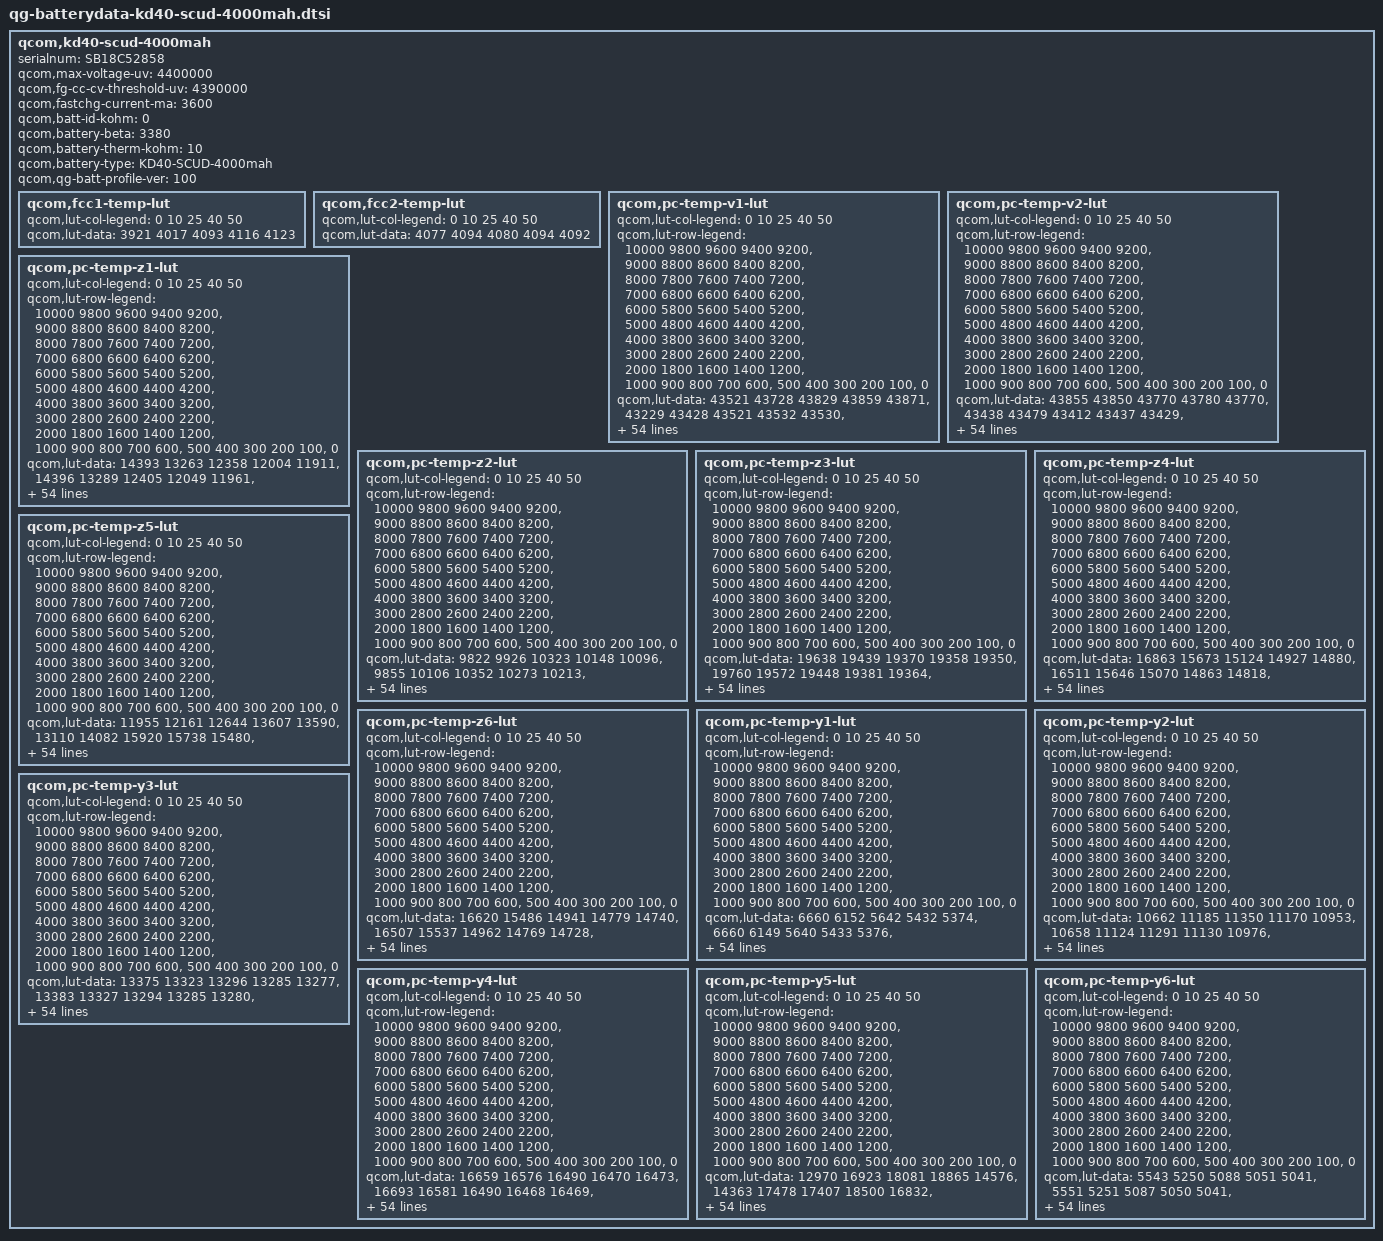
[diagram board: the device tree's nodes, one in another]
// SPDX-License-Identifier: GPL-2.0
/*
 * Copyright (c) 2018-2019, The Linux Foundation. All rights reserved.
 */

qcom,kd40-scud-4000mah {
	serialnum = "SB18C52858";
	qcom,max-voltage-uv = <4400000>;
	qcom,fg-cc-cv-threshold-uv = <4390000>;
	qcom,fastchg-current-ma = <3600>;
	qcom,batt-id-kohm = <0>;
	qcom,battery-beta = <3380>;
	qcom,battery-therm-kohm = <10>;
	qcom,battery-type = "KD40-SCUD-4000mah";
	qcom,qg-batt-profile-ver = <100>;

	qcom,fcc1-temp-lut {
		qcom,lut-col-legend = <0 10 25 40 50>;
		qcom,lut-data = <3921 4017 4093 4116 4123>;
	};

	qcom,fcc2-temp-lut {
		qcom,lut-col-legend = <0 10 25 40 50>;
		qcom,lut-data = <4077 4094 4080 4094 4092>;
	};

	qcom,pc-temp-v1-lut {
		qcom,lut-col-legend = <0 10 25 40 50>;
		qcom,lut-row-legend = <10000 9800 9600 9400 9200>,
			<9000 8800 8600 8400 8200>,
			<8000 7800 7600 7400 7200>,
			<7000 6800 6600 6400 6200>,
			<6000 5800 5600 5400 5200>,
			<5000 4800 4600 4400 4200>,
			<4000 3800 3600 3400 3200>,
			<3000 2800 2600 2400 2200>,
			<2000 1800 1600 1400 1200>,
			<1000 900 800 700 600>,
			<500 400 300 200 100>,
			<0>;
		qcom,lut-data = <43521 43728 43829 43859 43871>,
			<43229 43428 43521 43532 43530>,
			<42946 43147 43249 43263 43260>,
			<42661 42891 42990 43012 43011>,
			<42416 42644 42739 42766 42770>,
			<42184 42400 42495 42521 42530>,
			<41964 42165 42253 42284 42294>,
			<41751 41939 42015 42048 42059>,
			<41540 41718 41782 41814 41825>,
			<41338 41496 41555 41583 41594>,
			<41167 41285 41330 41357 41366>,
			<41014 41111 41122 41137 41144>,
			<40810 40956 40947 40927 40930>,
			<40491 40739 40774 40725 40725>,
			<40189 40405 40528 40519 40524>,
			<39990 40126 40231 40312 40328>,
			<39832 39964 40031 40122 40142>,
			<39707 39836 39905 39955 39966>,
			<39606 39716 39780 39797 39798>,
			<39503 39606 39639 39648 39646>,
			<39391 39484 39492 39500 39499>,
			<39278 39345 39344 39329 39326>,
			<39167 39203 39191 39139 39132>,
			<39058 39062 38981 38948 38942>,
			<38955 38916 38693 38746 38753>,
			<38857 38737 38527 38587 38596>,
			<38764 38537 38467 38486 38485>,
			<38674 38416 38419 38403 38392>,
			<38589 38346 38358 38321 38305>,
			<38510 38296 38295 38244 38227>,
			<38435 38259 38237 38177 38160>,
			<38367 38230 38182 38117 38100>,
			<38311 38200 38134 38065 38046>,
			<38262 38172 38091 38019 37995>,
			<38222 38146 38053 37976 37946>,
			<38187 38121 38016 37933 37896>,
			<38152 38094 37980 37890 37844>,
			<38117 38061 37940 37845 37792>,
			<38076 38019 37897 37798 37738>,
			<38018 37954 37834 37733 37667>,
			<37942 37852 37738 37633 37568>,
			<37838 37739 37625 37519 37454>,
			<37696 37608 37493 37391 37321>,
			<37549 37454 37345 37248 37175>,
			<37405 37290 37186 37091 37023>,
			<37280 37180 37086 36995 36935>,
			<37233 37149 37054 36964 36908>,
			<37198 37121 37036 36946 36886>,
			<37168 37103 37018 36929 36869>,
			<37132 37078 36989 36897 36832>,
			<37011 36942 36844 36728 36639>,
			<36640 36560 36446 36308 36208>,
			<36085 36002 35886 35744 35645>,
			<35328 35244 35123 34980 34877>,
			<34165 34085 33957 33808 33696>,
			<30000 30000 30000 30000 30000>;
	};

	qcom,pc-temp-v2-lut {
		qcom,lut-col-legend = <0 10 25 40 50>;
		qcom,lut-row-legend = <10000 9800 9600 9400 9200>,
			<9000 8800 8600 8400 8200>,
			<8000 7800 7600 7400 7200>,
			<7000 6800 6600 6400 6200>,
			<6000 5800 5600 5400 5200>,
			<5000 4800 4600 4400 4200>,
			<4000 3800 3600 3400 3200>,
			<3000 2800 2600 2400 2200>,
			<2000 1800 1600 1400 1200>,
			<1000 900 800 700 600>,
			<500 400 300 200 100>,
			<0>;
		qcom,lut-data = <43855 43850 43770 43780 43770>,
			<43438 43479 43412 43437 43429>,
			<43076 43148 43091 43127 43120>,
			<42780 42864 42815 42854 42849>,
			<42531 42615 42572 42610 42606>,
			<42282 42368 42331 42368 42364>,
			<42031 42126 42093 42129 42123>,
			<41796 41890 41859 41893 41887>,
			<41581 41661 41630 41662 41658>,
			<41377 41438 41406 41434 41432>,
			<41187 41223 41184 41209 41209>,
			<41005 41015 40967 40990 40989>,
			<40799 40822 40768 40779 40775>,
			<40570 40645 40588 40578 40569>,
			<40304 40435 40391 40378 40369>,
			<39931 40139 40141 40176 40176>,
			<39603 39868 39911 39985 39992>,
			<39453 39708 39760 39815 39818>,
			<39347 39574 39635 39655 39651>,
			<39200 39391 39495 39503 39497>,
			<39015 39169 39343 39358 39352>,
			<38842 38973 39161 39179 39176>,
			<38688 38805 38912 38939 38940>,
			<38545 38653 38686 38722 38724>,
			<38413 38518 38534 38562 38563>,
			<38291 38397 38412 38429 38428>,
			<38177 38291 38305 38319 38317>,
			<38072 38196 38211 38224 38222>,
			<37998 38107 38129 38139 38135>,
			<37947 38021 38056 38061 38055>,
			<37905 37948 37989 37993 37985>,
			<37870 37885 37925 37933 37922>,
			<37838 37835 37867 37877 37866>,
			<37806 37800 37816 37820 37813>,
			<37774 37772 37770 37764 37761>,
			<37733 37741 37725 37699 37688>,
			<37677 37709 37683 37627 37591>,
			<37617 37672 37635 37554 37497>,
			<37559 37623 37576 37480 37413>,
			<37495 37561 37509 37405 37334>,
			<37421 37483 37430 37329 37260>,
			<37331 37390 37343 37246 37179>,
			<37227 37271 37224 37135 37069>,
			<37103 37131 37096 37008 36944>,
			<36987 36986 36943 36861 36801>,
			<36905 36911 36886 36818 36760>,
			<36870 36885 36876 36808 36753>,
			<36833 36860 36859 36796 36739>,
			<36783 36817 36839 36775 36719>,
			<36704 36746 36792 36725 36662>,
			<36515 36539 36598 36494 36402>,
			<36117 36092 36153 36024 35926>,
			<35514 35465 35551 35408 35299>,
			<34652 34592 34743 34568 34452>,
			<33278 33349 33551 33346 33184>,
			<28800 28700 28452 28672 28678>;
	};

	qcom,pc-temp-z1-lut {
		qcom,lut-col-legend = <0 10 25 40 50>;
		qcom,lut-row-legend = <10000 9800 9600 9400 9200>,
			<9000 8800 8600 8400 8200>,
			<8000 7800 7600 7400 7200>,
			<7000 6800 6600 6400 6200>,
			<6000 5800 5600 5400 5200>,
			<5000 4800 4600 4400 4200>,
			<4000 3800 3600 3400 3200>,
			<3000 2800 2600 2400 2200>,
			<2000 1800 1600 1400 1200>,
			<1000 900 800 700 600>,
			<500 400 300 200 100>,
			<0>;
		qcom,lut-data = <14393 13263 12358 12004 11911>,
			<14396 13289 12405 12049 11961>,
			<14468 13271 12404 12051 11964>,
			<14441 13287 12397 12049 11964>,
			<14422 13266 12379 12045 11965>,
			<14420 13254 12371 12040 11963>,
			<14421 13248 12369 12041 11966>,
			<14417 13242 12366 12041 11968>,
			<14388 13236 12363 12043 11970>,
			<14349 13221 12363 12045 11971>,
			<14337 13209 12371 12046 11972>,
			<14327 13205 12377 12047 11972>,
			<14305 13189 12374 12047 11973>,
			<14218 13171 12368 12047 11974>,
			<14139 13139 12358 12047 11975>,
			<14102 13124 12345 12046 11976>,
			<14077 13131 12343 12046 11976>,
			<14074 13143 12352 12048 11978>,
			<14081 13156 12362 12050 11980>,
			<14084 13172 12370 12053 11983>,
			<14077 13188 12376 12055 11986>,
			<14069 13207 12382 12057 11987>,
			<14087 13221 12386 12059 11987>,
			<14131 13226 12391 12062 11988>,
			<14150 13231 12396 12066 11992>,
			<14165 13237 12401 12070 11997>,
			<14177 13244 12406 12074 12001>,
			<14175 13251 12412 12079 12005>,
			<14171 13256 12417 12082 12008>,
			<14179 13259 12422 12085 12011>,
			<14215 13260 12427 12088 12014>,
			<14240 13261 12432 12091 12017>,
			<14253 13272 12437 12095 12020>,
			<14265 13297 12442 12099 12023>,
			<14271 13310 12448 12103 12025>,
			<14276 13314 12455 12107 12028>,
			<14285 13320 12464 12112 12031>,
			<14302 13343 12472 12116 12033>,
			<14321 13370 12480 12119 12036>,
			<14339 13381 12488 12124 12039>,
			<14356 13389 12495 12129 12043>,
			<14361 13400 12503 12135 12047>,
			<14356 13420 12512 12138 12051>,
			<14378 13437 12521 12142 12054>,
			<14400 13446 12528 12146 12057>,
			<14390 13432 12534 12151 12061>,
			<14400 13436 12538 12150 12061>,
			<14391 13434 12540 12151 12062>,
			<14384 13436 12541 12154 12064>,
			<14413 13462 12544 12159 12068>,
			<14383 13465 12552 12165 12075>,
			<14404 13477 12571 12175 12083>,
			<14445 13528 12594 12190 12097>,
			<14456 13585 12626 12214 12116>,
			<14456 13585 12626 12214 12116>,
			<14456 13585 12626 12214 12116>;
	};

	qcom,pc-temp-z2-lut {
		qcom,lut-col-legend = <0 10 25 40 50>;
		qcom,lut-row-legend = <10000 9800 9600 9400 9200>,
			<9000 8800 8600 8400 8200>,
			<8000 7800 7600 7400 7200>,
			<7000 6800 6600 6400 6200>,
			<6000 5800 5600 5400 5200>,
			<5000 4800 4600 4400 4200>,
			<4000 3800 3600 3400 3200>,
			<3000 2800 2600 2400 2200>,
			<2000 1800 1600 1400 1200>,
			<1000 900 800 700 600>,
			<500 400 300 200 100>,
			<0>;
		qcom,lut-data = <9822 9926 10323 10148 10096>,
			<9855 10106 10352 10273 10213>,
			<9988 10186 10378 10300 10231>,
			<9962 10177 10365 10301 10190>,
			<9983 10173 10344 10314 10210>,
			<9993 10168 10267 10329 10280>,
			<9995 10162 10247 10284 10253>,
			<9999 10157 10238 10267 10243>,
			<10006 10153 10235 10269 10248>,
			<10014 10140 10239 10272 10256>,
			<10026 10122 10248 10274 10273>,
			<10043 10111 10260 10274 10291>,
			<10049 10103 10283 10274 10286>,
			<10046 10095 10307 10276 10264>,
			<10041 10080 10307 10281 10235>,
			<10027 10071 10299 10290 10193>,
			<10009 10078 10297 10287 10176>,
			<10007 10093 10304 10253 10190>,
			<10016 10118 10316 10228 10212>,
			<10023 10158 10362 10240 10231>,
			<10023 10197 10417 10272 10256>,
			<10023 10234 10448 10359 10347>,
			<10023 10272 10469 10533 10561>,
			<10021 10322 10468 10561 10616>,
			<10021 10360 10450 10397 10474>,
			<10025 10351 10429 10300 10382>,
			<10031 10320 10400 10452 10468>,
			<10045 10314 10381 10625 10566>,
			<10065 10333 10407 10594 10508>,
			<10083 10352 10449 10490 10349>,
			<10099 10367 10454 10412 10238>,
			<10115 10382 10450 10340 10150>,
			<10129 10391 10448 10318 10121>,
			<10142 10399 10447 10327 10139>,
			<10156 10407 10447 10342 10170>,
			<10170 10418 10461 10373 10216>,
			<10185 10431 10486 10412 10275>,
			<10200 10445 10515 10439 10329>,
			<10219 10462 10549 10462 10381>,
			<10252 10485 10569 10488 10405>,
			<10293 10513 10582 10523 10415>,
			<10324 10531 10589 10544 10424>,
			<10350 10541 10592 10555 10436>,
			<10339 10554 10598 10547 10438>,
			<10145 10588 10610 10486 10421>,
			<9688 10818 10666 10472 10415>,
			<9746 10846 10647 10462 10445>,
			<9796 10870 10654 10494 10420>,
			<9826 11286 10660 10492 10464>,
			<9883 11781 10712 10599 10550>,
			<9865 11162 10749 10580 10466>,
			<9756 10869 10705 10364 10242>,
			<9674 10797 10614 10276 10157>,
			<9595 10723 10544 10200 10085>,
			<9595 10723 10544 10200 10085>,
			<9595 10723 10544 10200 10085>;
	};

	qcom,pc-temp-z3-lut {
		qcom,lut-col-legend = <0 10 25 40 50>;
		qcom,lut-row-legend = <10000 9800 9600 9400 9200>,
			<9000 8800 8600 8400 8200>,
			<8000 7800 7600 7400 7200>,
			<7000 6800 6600 6400 6200>,
			<6000 5800 5600 5400 5200>,
			<5000 4800 4600 4400 4200>,
			<4000 3800 3600 3400 3200>,
			<3000 2800 2600 2400 2200>,
			<2000 1800 1600 1400 1200>,
			<1000 900 800 700 600>,
			<500 400 300 200 100>,
			<0>;
		qcom,lut-data = <19638 19439 19370 19358 19350>,
			<19760 19572 19448 19381 19364>,
			<19757 19607 19456 19392 19374>,
			<19681 19653 19449 19390 19379>,
			<19671 19708 19492 19398 19382>,
			<19673 19706 19509 19442 19419>,
			<19676 19703 19504 19440 19419>,
			<19679 19695 19500 19436 19419>,
			<19684 19686 19495 19430 19416>,
			<19689 19679 19489 19424 19413>,
			<19690 19672 19479 19417 19410>,
			<19690 19651 19466 19410 19407>,
			<19696 19615 19451 19404 19401>,
			<19728 19608 19438 19399 19392>,
			<19753 19623 19444 19398 19386>,
			<19741 19632 19465 19398 19383>,
			<19715 19612 19469 19397 19380>,
			<19693 19581 19448 19388 19377>,
			<19674 19558 19430 19377 19373>,
			<19663 19540 19421 19371 19366>,
			<19657 19534 19416 19366 19357>,
			<19654 19535 19419 19371 19360>,
			<19657 19537 19427 19387 19372>,
			<19666 19541 19431 19389 19375>,
			<19677 19546 19435 19369 19356>,
			<19691 19548 19436 19357 19344>,
			<19704 19551 19425 19371 19381>,
			<19714 19551 19416 19393 19425>,
			<19721 19550 19419 19408 19425>,
			<19722 19549 19425 19421 19417>,
			<19720 19547 19432 19422 19408>,
			<19718 19544 19442 19415 19396>,
			<19712 19541 19444 19407 19385>,
			<19703 19538 19443 19400 19378>,
			<19693 19534 19441 19393 19372>,
			<19680 19529 19437 19386 19364>,
			<19666 19523 19432 19379 19357>,
			<19649 19518 19428 19374 19353>,
			<19631 19512 19425 19369 19351>,
			<19611 19509 19421 19368 19350>,
			<19594 19506 19415 19368 19351>,
			<19587 19502 19412 19368 19352>,
			<19584 19496 19412 19367 19356>,
			<19541 19491 19411 19367 19358>,
			<19422 19485 19407 19366 19359>,
			<19277 19441 19390 19355 19348>,
			<19273 19428 19390 19354 19340>,
			<19269 19424 19376 19344 19336>,
			<19267 19353 19372 19341 19328>,
			<19266 19285 19369 19330 19319>,
			<19266 19386 19364 19336 19337>,
			<19268 19425 19363 19360 19357>,
			<19270 19425 19363 19363 19357>,
			<19272 19413 19362 19365 19361>,
			<19272 19413 19362 19365 19361>,
			<19272 19413 19362 19365 19361>;
	};

	qcom,pc-temp-z4-lut {
		qcom,lut-col-legend = <0 10 25 40 50>;
		qcom,lut-row-legend = <10000 9800 9600 9400 9200>,
			<9000 8800 8600 8400 8200>,
			<8000 7800 7600 7400 7200>,
			<7000 6800 6600 6400 6200>,
			<6000 5800 5600 5400 5200>,
			<5000 4800 4600 4400 4200>,
			<4000 3800 3600 3400 3200>,
			<3000 2800 2600 2400 2200>,
			<2000 1800 1600 1400 1200>,
			<1000 900 800 700 600>,
			<500 400 300 200 100>,
			<0>;
		qcom,lut-data = <16863 15673 15124 14927 14880>,
			<16511 15646 15070 14863 14818>,
			<17225 15311 14929 14810 14776>,
			<17482 15384 14846 14771 14746>,
			<16916 15569 14933 14768 14740>,
			<16522 15355 14951 14835 14812>,
			<16238 15205 14885 14801 14784>,
			<16017 15106 14839 14774 14761>,
			<15852 15031 14803 14756 14746>,
			<15714 14975 14785 14744 14735>,
			<15573 14931 14779 14738 14727>,
			<15439 14883 14773 14734 14722>,
			<15354 14838 14756 14727 14718>,
			<15310 14825 14738 14718 14715>,
			<15269 14828 14740 14712 14711>,
			<15212 14829 14746 14709 14706>,
			<15150 14809 14743 14705 14701>,
			<15095 14779 14717 14701 14695>,
			<15045 14760 14703 14697 14690>,
			<15009 14746 14704 14693 14685>,
			<14988 14739 14706 14689 14681>,
			<14971 14736 14708 14694 14687>,
			<14951 14735 14712 14717 14715>,
			<14929 14740 14745 14753 14753>,
			<14906 14751 14870 14834 14821>,
			<14880 14794 14923 14876 14858>,
			<14856 14885 14900 14846 14804>,
			<14838 14911 14867 14798 14734>,
			<14823 14902 14840 14763 14720>,
			<14816 14888 14812 14733 14714>,
			<14812 14866 14786 14720 14710>,
			<14809 14838 14762 14714 14707>,
			<14805 14816 14745 14709 14704>,
			<14800 14796 14733 14704 14698>,
			<14792 14778 14725 14701 14694>,
			<14782 14761 14721 14703 14697>,
			<14772 14746 14717 14705 14700>,
			<14763 14733 14715 14704 14701>,
			<14754 14723 14712 14703 14701>,
			<14747 14723 14713 14703 14703>,
			<14741 14723 14718 14711 14709>,
			<14736 14722 14720 14715 14712>,
			<14732 14715 14711 14708 14707>,
			<14771 14708 14705 14705 14704>,
			<14850 14700 14703 14708 14708>,
			<14939 14676 14669 14676 14677>,
			<14933 14680 14661 14669 14672>,
			<14926 14673 14658 14661 14660>,
			<14919 14742 14647 14643 14644>,
			<14911 14809 14642 14639 14636>,
			<14911 14705 14660 14656 14645>,
			<14938 14684 14684 14659 14658>,
			<14965 14699 14691 14661 14663>,
			<14990 14728 14698 14663 14662>,
			<14990 14728 14698 14663 14662>,
			<14990 14728 14698 14663 14662>;
	};

	qcom,pc-temp-z5-lut {
		qcom,lut-col-legend = <0 10 25 40 50>;
		qcom,lut-row-legend = <10000 9800 9600 9400 9200>,
			<9000 8800 8600 8400 8200>,
			<8000 7800 7600 7400 7200>,
			<7000 6800 6600 6400 6200>,
			<6000 5800 5600 5400 5200>,
			<5000 4800 4600 4400 4200>,
			<4000 3800 3600 3400 3200>,
			<3000 2800 2600 2400 2200>,
			<2000 1800 1600 1400 1200>,
			<1000 900 800 700 600>,
			<500 400 300 200 100>,
			<0>;
		qcom,lut-data = <11955 12161 12644 13607 13590>,
			<13110 14082 15920 15738 15480>,
			<13222 16305 17833 17849 17703>,
			<13260 16001 19078 18722 19600>,
			<13985 14468 18179 19651 20699>,
			<14533 15029 17106 19117 19705>,
			<14961 15591 17662 19504 20304>,
			<15292 16161 18361 19944 21031>,
			<15523 16794 19378 20568 21918>,
			<15712 17669 19724 21036 22760>,
			<15867 18322 19522 20995 23575>,
			<16004 18276 19223 20722 24149>,
			<16284 18108 18874 20647 23738>,
			<17002 18590 18568 20772 22653>,
			<17471 21540 19871 21392 22482>,
			<17401 23222 23479 22788 23040>,
			<17267 22281 24349 23284 23688>,
			<17203 21284 23285 22600 24615>,
			<17153 21347 22698 22122 25301>,
			<17101 21876 23124 22039 24775>,
			<17051 22897 23987 21949 23788>,
			<17067 25775 26569 24670 25333>,
			<17352 29537 30494 32369 31196>,
			<18042 35232 31652 33417 32192>,
			<19008 40412 31794 23767 22636>,
			<20656 42405 31056 17640 16292>,
			<22822 43942 25450 17666 19259>,
			<25709 43862 20879 18286 23411>,
			<29023 41217 20785 20354 25015>,
			<31979 38390 20844 23884 25980>,
			<35159 36369 21698 25856 25880>,
			<36898 34914 24711 27058 24742>,
			<37514 34438 27493 28145 24316>,
			<37852 34156 29967 29368 25456>,
			<37355 34009 32011 30103 26403>,
			<35881 33918 33840 30228 26264>,
			<34325 33890 35049 30237 25942>,
			<32058 33998 35005 29757 25607>,
			<29831 34237 34578 28314 25169>,
			<27965 34973 33538 27058 24499>,
			<26545 36445 30643 25797 23263>,
			<27007 36513 29208 24897 22669>,
			<29147 33560 29462 24448 23642>,
			<25662 33223 29323 24007 24145>,
			<17977 34550 28050 23483 24026>,
			<11704 31001 28545 23762 23188>,
			<11683 24158 28957 23175 20267>,
			<11621 23506 23639 21341 20127>,
			<11582 16781 23353 23010 21004>,
			<11583 12079 23771 21191 20431>,
			<11606 22306 20897 19327 22265>,
			<11704 21837 17577 21134 22879>,
			<11581 19332 16501 20390 20230>,
			<11465 16541 15594 18936 19056>,
			<11465 16541 15594 18936 19056>,
			<11465 16541 15594 18936 19056>;
	};

	qcom,pc-temp-z6-lut {
		qcom,lut-col-legend = <0 10 25 40 50>;
		qcom,lut-row-legend = <10000 9800 9600 9400 9200>,
			<9000 8800 8600 8400 8200>,
			<8000 7800 7600 7400 7200>,
			<7000 6800 6600 6400 6200>,
			<6000 5800 5600 5400 5200>,
			<5000 4800 4600 4400 4200>,
			<4000 3800 3600 3400 3200>,
			<3000 2800 2600 2400 2200>,
			<2000 1800 1600 1400 1200>,
			<1000 900 800 700 600>,
			<500 400 300 200 100>,
			<0>;
		qcom,lut-data = <16620 15486 14941 14779 14740>,
			<16507 15537 14962 14769 14728>,
			<16785 15400 14903 14752 14715>,
			<16839 15444 14862 14734 14705>,
			<16562 15546 14920 14737 14704>,
			<16374 15443 14936 14790 14756>,
			<16240 15367 14903 14774 14745>,
			<16135 15313 14881 14761 14735>,
			<16058 15271 14863 14750 14727>,
			<15992 15241 14851 14742 14721>,
			<15921 15214 14843 14736 14716>,
			<15850 15175 14836 14730 14712>,
			<15799 15133 14819 14723 14707>,
			<15768 15121 14803 14717 14700>,
			<15736 15121 14805 14713 14695>,
			<15689 15121 14816 14712 14691>,
			<15636 15103 14816 14709 14687>,
			<15596 15077 14795 14703 14684>,
			<15561 15062 14782 14696 14679>,
			<15544 15050 14779 14690 14673>,
			<15539 15047 14778 14687 14667>,
			<15537 15049 14780 14691 14671>,
			<15537 15052 14786 14708 14690>,
			<15540 15058 14806 14728 14708>,
			<15542 15067 14862 14753 14729>,
			<15545 15090 14886 14765 14738>,
			<15548 15131 14871 14760 14736>,
			<15552 15142 14854 14753 14731>,
			<15556 15140 14844 14747 14726>,
			<15557 15135 14837 14742 14720>,
			<15559 15126 14831 14736 14714>,
			<15559 15114 14826 14731 14706>,
			<15559 15106 14821 14725 14700>,
			<15559 15099 14817 14719 14693>,
			<15556 15092 14812 14714 14689>,
			<15551 15085 14809 14711 14685>,
			<15546 15080 14806 14709 14683>,
			<15541 15076 14804 14706 14681>,
			<15537 15073 14803 14703 14679>,
			<15532 15074 14802 14703 14679>,
			<15528 15079 14804 14707 14683>,
			<15529 15081 14804 14709 14685>,
			<15534 15079 14802 14706 14685>,
			<15532 15079 14800 14705 14686>,
			<15519 15079 14799 14706 14689>,
			<15492 15054 14778 14688 14670>,
			<15488 15049 14774 14684 14664>,
			<15482 15045 14766 14675 14657>,
			<15481 15040 14760 14666 14645>,
			<15480 15038 14758 14661 14638>,
			<15485 15049 14765 14671 14652>,
			<15512 15071 14779 14687 14671>,
			<15536 15087 14788 14694 14677>,
			<15573 15114 14798 14701 14683>,
			<15573 15114 14798 14701 14683>,
			<15573 15114 14798 14701 14683>;
	};

	qcom,pc-temp-y1-lut {
		qcom,lut-col-legend = <0 10 25 40 50>;
		qcom,lut-row-legend = <10000 9800 9600 9400 9200>,
			<9000 8800 8600 8400 8200>,
			<8000 7800 7600 7400 7200>,
			<7000 6800 6600 6400 6200>,
			<6000 5800 5600 5400 5200>,
			<5000 4800 4600 4400 4200>,
			<4000 3800 3600 3400 3200>,
			<3000 2800 2600 2400 2200>,
			<2000 1800 1600 1400 1200>,
			<1000 900 800 700 600>,
			<500 400 300 200 100>,
			<0>;
		qcom,lut-data = <6660 6152 5642 5432 5374>,
			<6660 6149 5640 5433 5376>,
			<6660 6145 5639 5433 5378>,
			<6660 6141 5637 5433 5378>,
			<6660 6137 5635 5432 5379>,
			<6659 6134 5634 5432 5379>,
			<6658 6131 5631 5432 5378>,
			<6657 6129 5629 5432 5377>,
			<6656 6133 5627 5431 5379>,
			<6656 6137 5625 5430 5380>,
			<6660 6135 5625 5430 5380>,
			<6670 6131 5624 5429 5380>,
			<6673 6128 5623 5429 5380>,
			<6676 6119 5621 5430 5380>,
			<6677 6115 5620 5430 5381>,
			<6684 6122 5630 5431 5382>,
			<6692 6129 5640 5432 5384>,
			<6691 6136 5638 5433 5384>,
			<6685 6142 5634 5435 5385>,
			<6685 6141 5634 5435 5385>,
			<6691 6135 5636 5436 5387>,
			<6696 6134 5638 5436 5388>,
			<6697 6138 5643 5438 5389>,
			<6698 6141 5647 5440 5390>,
			<6706 6143 5649 5442 5392>,
			<6718 6144 5652 5444 5394>,
			<6721 6149 5655 5446 5395>,
			<6721 6159 5659 5448 5397>,
			<6722 6163 5664 5451 5399>,
			<6727 6163 5668 5453 5400>,
			<6730 6161 5673 5456 5402>,
			<6724 6155 5678 5459 5405>,
			<6714 6150 5683 5462 5407>,
			<6707 6155 5687 5465 5410>,
			<6700 6166 5693 5469 5412>,
			<6699 6170 5697 5472 5415>,
			<6713 6170 5701 5474 5417>,
			<6722 6171 5704 5476 5419>,
			<6718 6180 5706 5477 5421>,
			<6715 6192 5709 5479 5422>,
			<6727 6203 5712 5482 5424>,
			<6738 6198 5721 5485 5427>,
			<6759 6218 5721 5488 5428>,
			<6768 6224 5732 5491 5433>,
			<6779 6233 5736 5497 5436>,
			<6778 6248 5751 5502 5441>,
			<6778 6229 5757 5503 5441>,
			<6782 6249 5758 5504 5441>,
			<6793 6242 5767 5505 5441>,
			<6773 6245 5765 5503 5441>,
			<6778 6264 5770 5507 5445>,
			<6813 6273 5784 5516 5450>,
			<6825 6285 5807 5530 5461>,
			<6851 6297 5839 5548 5477>,
			<6851 6297 5839 5548 5477>,
			<6851 6297 5839 5548 5477>;
	};

	qcom,pc-temp-y2-lut {
		qcom,lut-col-legend = <0 10 25 40 50>;
		qcom,lut-row-legend = <10000 9800 9600 9400 9200>,
			<9000 8800 8600 8400 8200>,
			<8000 7800 7600 7400 7200>,
			<7000 6800 6600 6400 6200>,
			<6000 5800 5600 5400 5200>,
			<5000 4800 4600 4400 4200>,
			<4000 3800 3600 3400 3200>,
			<3000 2800 2600 2400 2200>,
			<2000 1800 1600 1400 1200>,
			<1000 900 800 700 600>,
			<500 400 300 200 100>,
			<0>;
		qcom,lut-data = <10662 11185 11350 11170 10953>,
			<10658 11124 11291 11130 10976>,
			<10654 11065 11233 11087 10981>,
			<10648 11011 11179 11044 10973>,
			<10643 10961 11127 11003 10957>,
			<10637 10917 11076 10964 10934>,
			<10627 10876 11022 10920 10882>,
			<10612 10842 10992 10895 10842>,
			<10569 10812 10983 10884 10824>,
			<10528 10789 10975 10878 10812>,
			<10585 10780 10954 10878 10803>,
			<10734 10775 10917 10876 10796>,
			<10824 10792 10888 10857 10794>,
			<10891 10885 10855 10789 10792>,
			<10915 10959 10844 10762 10792>,
			<10888 11002 10920 10802 10789>,
			<10861 11034 11021 10853 10790>,
			<10887 11061 11075 10888 10816>,
			<10943 11083 11121 10928 10862>,
			<10972 11094 11195 11012 10913>,
			<10987 11100 11302 11148 10972>,
			<11007 11114 11335 11188 11007>,
			<11036 11152 11276 11162 11025>,
			<11059 11186 11231 11137 11041>,
			<11066 11206 11250 11126 11064>,
			<11072 11224 11281 11119 11091>,
			<11088 11246 11295 11154 11114>,
			<11118 11268 11303 11237 11138>,
			<11128 11283 11309 11269 11166>,
			<11128 11293 11332 11280 11215>,
			<11125 11301 11349 11294 11243>,
			<11086 11308 11337 11333 11260>,
			<11022 11311 11320 11361 11282>,
			<10977 11296 11312 11342 11313>,
			<10934 11259 11306 11299 11346>,
			<10760 11225 11293 11255 11337>,
			<10100 11190 11264 11198 11254>,
			<9716 11152 11247 11179 11181>,
			<9689 11109 11246 11203 11129>,
			<9678 11058 11240 11196 11106>,
			<9674 11002 11206 11172 11064>,
			<9670 10965 11212 11172 11092>,
			<9669 10911 11205 11143 11112>,
			<9664 10807 11181 11155 11096>,
			<9659 10483 11135 11144 11031>,
			<9657 10538 11014 10976 10908>,
			<9656 10400 10982 10958 10859>,
			<9655 10116 10962 10962 10849>,
			<9654 9807 10942 10976 10900>,
			<9654 9749 10925 11011 10894>,
			<9653 9698 10901 10956 10822>,
			<9653 9674 10806 10897 10774>,
			<9653 9662 10713 10820 10667>,
			<9653 9656 10626 10724 10590>,
			<9653 9656 10626 10724 10590>,
			<9653 9656 10626 10724 10590>;
	};

	qcom,pc-temp-y3-lut {
		qcom,lut-col-legend = <0 10 25 40 50>;
		qcom,lut-row-legend = <10000 9800 9600 9400 9200>,
			<9000 8800 8600 8400 8200>,
			<8000 7800 7600 7400 7200>,
			<7000 6800 6600 6400 6200>,
			<6000 5800 5600 5400 5200>,
			<5000 4800 4600 4400 4200>,
			<4000 3800 3600 3400 3200>,
			<3000 2800 2600 2400 2200>,
			<2000 1800 1600 1400 1200>,
			<1000 900 800 700 600>,
			<500 400 300 200 100>,
			<0>;
		qcom,lut-data = <13375 13323 13296 13285 13277>,
			<13383 13327 13294 13285 13280>,
			<13391 13330 13294 13285 13282>,
			<13399 13333 13293 13285 13283>,
			<13405 13336 13294 13285 13283>,
			<13409 13339 13294 13286 13283>,
			<13411 13342 13294 13286 13282>,
			<13414 13344 13295 13287 13282>,
			<13423 13345 13296 13288 13284>,
			<13432 13347 13297 13289 13286>,
			<13440 13348 13299 13290 13287>,
			<13446 13350 13302 13291 13288>,
			<13442 13354 13307 13291 13288>,
			<13411 13359 13314 13292 13289>,
			<13388 13361 13316 13292 13289>,
			<13379 13353 13312 13291 13289>,
			<13374 13345 13308 13291 13289>,
			<13374 13343 13308 13292 13290>,
			<13376 13342 13307 13295 13291>,
			<13374 13338 13308 13296 13292>,
			<13367 13331 13310 13297 13294>,
			<13360 13326 13310 13297 13294>,
			<13356 13324 13304 13291 13288>,
			<13353 13322 13297 13286 13282>,
			<13349 13319 13295 13284 13281>,
			<13344 13317 13293 13283 13280>,
			<13337 13317 13292 13283 13280>,
			<13328 13317 13291 13282 13280>,
			<13325 13316 13291 13282 13280>,
			<13325 13314 13293 13281 13279>,
			<13325 13312 13294 13281 13278>,
			<13329 13311 13294 13281 13278>,
			<13336 13311 13294 13282 13278>,
			<13341 13312 13294 13282 13279>,
			<13345 13315 13294 13282 13280>,
			<13351 13318 13294 13282 13280>,
			<13358 13320 13294 13282 13279>,
			<13363 13323 13295 13282 13278>,
			<13365 13326 13296 13283 13279>,
			<13373 13328 13297 13283 13279>,
			<13407 13330 13297 13284 13280>,
			<13433 13330 13296 13284 13281>,
			<13431 13328 13293 13283 13281>,
			<13504 13328 13294 13283 13281>,
			<13620 13329 13293 13281 13277>,
			<13810 13342 13298 13285 13282>,
			<13926 13348 13303 13289 13287>,
			<14058 13351 13305 13293 13290>,
			<14185 13365 13312 13296 13292>,
			<14307 13408 13318 13299 13293>,
			<14414 13444 13316 13293 13288>,
			<14527 13485 13317 13292 13288>,
			<14703 13613 13328 13299 13292>,
			<14940 13896 13342 13306 13302>,
			<14940 13896 13342 13306 13302>,
			<14940 13896 13342 13306 13302>;
	};

	qcom,pc-temp-y4-lut {
		qcom,lut-col-legend = <0 10 25 40 50>;
		qcom,lut-row-legend = <10000 9800 9600 9400 9200>,
			<9000 8800 8600 8400 8200>,
			<8000 7800 7600 7400 7200>,
			<7000 6800 6600 6400 6200>,
			<6000 5800 5600 5400 5200>,
			<5000 4800 4600 4400 4200>,
			<4000 3800 3600 3400 3200>,
			<3000 2800 2600 2400 2200>,
			<2000 1800 1600 1400 1200>,
			<1000 900 800 700 600>,
			<500 400 300 200 100>,
			<0>;
		qcom,lut-data = <16659 16576 16490 16470 16473>,
			<16693 16581 16490 16468 16469>,
			<16730 16588 16491 16467 16466>,
			<16765 16595 16492 16466 16464>,
			<16793 16600 16494 16466 16463>,
			<16809 16603 16496 16466 16463>,
			<16818 16603 16499 16467 16465>,
			<16825 16605 16502 16468 16466>,
			<16832 16617 16506 16470 16466>,
			<16842 16632 16510 16472 16465>,
			<16884 16641 16513 16474 16466>,
			<16969 16649 16516 16477 16469>,
			<17043 16681 16522 16482 16471>,
			<17123 16778 16539 16490 16475>,
			<17147 16817 16556 16499 16480>,
			<16924 16778 16567 16507 16485>,
			<16707 16745 16581 16515 16492>,
			<16730 16746 16610 16526 16500>,
			<16782 16748 16649 16540 16511>,
			<16782 16730 16676 16567 16531>,
			<16739 16662 16698 16611 16564>,
			<16701 16612 16697 16618 16571>,
			<16674 16581 16600 16562 16537>,
			<16650 16560 16512 16508 16501>,
			<16626 16547 16492 16483 16480>,
			<16603 16539 16481 16468 16466>,
			<16584 16535 16481 16468 16466>,
			<16566 16532 16483 16469 16466>,
			<16561 16528 16487 16472 16468>,
			<16565 16522 16491 16479 16475>,
			<16571 16516 16495 16488 16484>,
			<16577 16511 16497 16500 16495>,
			<16584 16508 16499 16510 16506>,
			<16595 16512 16501 16513 16519>,
			<16612 16521 16503 16514 16530>,
			<16638 16533 16504 16510 16525>,
			<16686 16549 16504 16494 16497>,
			<16726 16565 16504 16482 16479>,
			<16751 16579 16499 16474 16471>,
			<16760 16589 16495 16473 16471>,
			<16760 16595 16494 16478 16479>,
			<16744 16583 16495 16481 16484>,
			<16710 16559 16482 16468 16468>,
			<16699 16566 16488 16472 16471>,
			<16701 16587 16477 16450 16446>,
			<16719 16596 16490 16462 16460>,
			<16739 16622 16504 16474 16478>,
			<16773 16689 16524 16501 16516>,
			<16822 16745 16554 16542 16563>,
			<16877 16790 16602 16581 16593>,
			<16897 16823 16588 16523 16510>,
			<16879 16814 16570 16491 16484>,
			<16858 16839 16601 16504 16489>,
			<16864 16900 16668 16546 16523>,
			<16864 16900 16668 16546 16523>,
			<16864 16900 16668 16546 16523>;
	};

	qcom,pc-temp-y5-lut {
		qcom,lut-col-legend = <0 10 25 40 50>;
		qcom,lut-row-legend = <10000 9800 9600 9400 9200>,
			<9000 8800 8600 8400 8200>,
			<8000 7800 7600 7400 7200>,
			<7000 6800 6600 6400 6200>,
			<6000 5800 5600 5400 5200>,
			<5000 4800 4600 4400 4200>,
			<4000 3800 3600 3400 3200>,
			<3000 2800 2600 2400 2200>,
			<2000 1800 1600 1400 1200>,
			<1000 900 800 700 600>,
			<500 400 300 200 100>,
			<0>;
		qcom,lut-data = <12970 16923 18081 18865 14576>,
			<14363 17478 17407 18500 16832>,
			<15484 17890 16754 18144 18114>,
			<16290 18147 16159 17806 18687>,
			<16737 18242 15657 17495 18811>,
			<16747 18162 15282 17218 18506>,
			<16245 17913 14996 16961 16720>,
			<15957 17542 14757 16734 15709>,
			<17334 16678 14480 16507 16543>,
			<18910 15765 14289 16272 17460>,
			<17718 15335 14377 16052 17342>,
			<14861 15020 14625 15813 16907>,
			<14761 14933 14801 15437 16489>,
			<17584 14932 14951 14839 16050>,
			<18955 15167 14984 14309 15603>,
			<18128 17137 14478 13818 15102>,
			<17348 19096 13990 13550 14692>,
			<18059 19762 13979 13585 14407>,
			<19420 20151 14018 13691 14208>,
			<19714 20170 14896 13880 14209>,
			<19755 20103 18234 14306 14266>,
			<19822 20149 20083 15145 14630>,
			<20001 20683 20681 17560 16332>,
			<20146 21029 20923 19126 17657>,
			<20198 20593 20417 19275 18145>,
			<20233 20083 19476 19289 18470>,
			<19286 20345 18873 19019 18482>,
			<16311 20984 18402 18369 18409>,
			<15135 21064 18430 17735 18080>,
			<14908 20663 19799 17032 16726>,
			<14820 20170 21038 16778 15980>,
			<15334 19531 21519 17098 15942>,
			<16108 19107 21803 17661 15953>,
			<16579 19611 21855 18477 16924>,
			<17030 20581 21879 19513 18898>,
			<16798 20750 21927 20179 19652>,
			<14504 20732 22011 20669 19963>,
			<13129 20732 22044 20831 20174>,
			<13097 20356 22059 20493 20111>,
			<13129 19826 21936 19910 19568>,
			<13464 19152 20716 19267 18843>,
			<13462 19285 20139 19385 19470>,
			<13026 18792 18851 19448 19811>,
			<12999 17273 18569 19014 19919>,
			<12731 15652 17862 18532 18529>,
			<12736 15691 17437 17303 16286>,
			<12795 15316 17933 17169 17115>,
			<12841 14052 16779 16711 15688>,
			<12854 12929 16697 16211 15059>,
			<13390 13494 16487 15956 14733>,
			<13732 13478 16614 15972 15380>,
			<13272 13030 17289 17377 16234>,
			<12931 12984 18072 19703 17147>,
			<13027 12901 18674 21186 22028>,
			<13027 12901 18674 21186 22028>,
			<13027 12901 18674 21186 22028>;
	};

	qcom,pc-temp-y6-lut {
		qcom,lut-col-legend = <0 10 25 40 50>;
		qcom,lut-row-legend = <10000 9800 9600 9400 9200>,
			<9000 8800 8600 8400 8200>,
			<8000 7800 7600 7400 7200>,
			<7000 6800 6600 6400 6200>,
			<6000 5800 5600 5400 5200>,
			<5000 4800 4600 4400 4200>,
			<4000 3800 3600 3400 3200>,
			<3000 2800 2600 2400 2200>,
			<2000 1800 1600 1400 1200>,
			<1000 900 800 700 600>,
			<500 400 300 200 100>,
			<0>;
		qcom,lut-data = <5543 5250 5088 5051 5041>,
			<5551 5251 5087 5050 5041>,
			<5557 5252 5087 5050 5042>,
			<5561 5253 5087 5050 5043>,
			<5564 5253 5088 5050 5043>,
			<5564 5253 5088 5051 5043>,
			<5561 5253 5089 5052 5043>,
			<5559 5252 5091 5053 5043>,
			<5561 5254 5092 5054 5044>,
			<5565 5257 5094 5055 5046>,
			<5578 5259 5097 5056 5048>,
			<5599 5261 5100 5058 5049>,
			<5606 5270 5105 5060 5050>,
			<5608 5299 5114 5063 5051>,
			<5604 5311 5120 5065 5053>,
			<5541 5295 5122 5067 5055>,
			<5481 5281 5124 5069 5057>,
			<5487 5281 5131 5073 5060>,
			<5502 5280 5141 5079 5064>,
			<5501 5273 5150 5088 5071>,
			<5486 5247 5157 5101 5081>,
			<5474 5230 5157 5103 5083>,
			<5466 5220 5125 5082 5068>,
			<5460 5213 5095 5063 5054>,
			<5456 5208 5088 5054 5046>,
			<5452 5206 5084 5049 5042>,
			<5449 5206 5084 5049 5041>,
			<5446 5207 5084 5050 5042>,
			<5446 5207 5085 5050 5043>,
			<5456 5205 5088 5052 5045>,
			<5470 5205 5091 5055 5046>,
			<5487 5205 5092 5059 5049>,
			<5509 5206 5094 5062 5053>,
			<5535 5210 5095 5063 5057>,
			<5565 5218 5096 5064 5062>,
			<5599 5228 5097 5063 5060>,
			<5636 5238 5099 5059 5051>,
			<5678 5250 5100 5056 5046>,
			<5727 5263 5100 5054 5045>,
			<5780 5276 5100 5054 5045>,
			<5837 5290 5101 5056 5048>,
			<5878 5295 5102 5058 5051>,
			<5878 5294 5097 5054 5046>,
			<5974 5314 5101 5055 5048>,
			<6101 5349 5099 5048 5038>,
			<6280 5407 5110 5056 5046>,
			<6381 5451 5119 5062 5056>,
			<6502 5503 5128 5073 5068>,
			<6618 5566 5143 5087 5084>,
			<6728 5645 5162 5100 5093>,
			<6818 5717 5158 5079 5065>,
			<6907 5811 5158 5071 5059>,
			<7043 6001 5186 5082 5065>,
			<7234 6300 5230 5101 5085>,
			<7234 6300 5230 5101 5085>,
			<7234 6300 5230 5101 5085>;
	};

};
